# D1H register map
Vendor: Allwinner; File version: 1.0
Registers are 32-bit, read-write, reset 0x0 unless marked. A register's access mark holds for its fields unless they carry their own. Offsets are from the block's base; [hi:lo] are bit positions; lines under a group give offsets from that group; {n}, {i} and the like mark numbered series.

## USB1 (part 2 of 2) — USB2.0 HOST
Base 0x04200000
0x404 ohci_control_status_partition group — OHCI Control and Status Partition Register
  0x00 hc_control — OHCI Control Register
    [10] remote_wakeup_enable — This bit is used by HCD to enable or disable the remote wakeup feature upon the detection of upstream resume signaling. When this bit is set and the ResumeDetected bit in HcInterruptStatus is set, a remote wakeup is signaled to the host system. Setting this bit has no impact on the generation of hardware interrupt.
    [9] remote_wakeup_connected — This bit indicates whether HC supports remote wakeup signaling. If remote wakeup is supported and used by the system, it is the responsibility of system firmware to set this bit during POST. HC clear the bit upon a hardware reset but does not alter it upon a software reset. Remote wakeup signaling of the host system is host-bus-specific and is not described in this specification.
    [8] interrupt_routing — InterruptRouting This bit determines the routing of interrupts generated by events registered in HcInterruptStatus. If clear, all interrupt are routed to the normal host bus interrupt mechanism. If set interrupts are routed to the System Management Interrupt. HCD clears this bit upon a hardware reset, but it does not alter this bit upon a software reset. HCD uses this bit as a tag to indicate the ownership of HC.
    [7:6] host_controller_functional_state_for_usb — A transition to USBOperational from another state causes SOF generation to begin 1 ms later. HCD may determine whether HC has begun sending SOFs by reading the StartoFrame field of HcInterruptStatus. . This field may be changed by HC only when in the USBSUSPEND state. HC may move from the USBSUSPEND state to the USBRESUME state after detecting the resume signaling from a downstream port. . HC enters USBSUSPEND after a software reset, whereas it enters USBRESET after a hardware reset. The latter also resets the Root Hub and asserts subsequent reset signaling to downstream ports.
      0=USB_RESET; 1=USB_RESUME; 2=USB_OPERATIONAL; 3=USB_SUSPEND
    [5] bulk_list_enable — This bit is set to enable the processing of the Bulk list in the next Frame. If cleared by HCD, the processing of the Bulk list does not occur after the next SOF. HC checks this bit whenever it determines to process the list. When disabled, HCD may modify the list. If HcBulkCurrentED is pointing to an ED to be removed, HCD must advance the pointer by updating HcBulkCurrentED before re-enabling processing of the list.
    [3] control_list_enable — This bit is set to enable the processing of the Control list in the next Frame. If cleared by HCD, the processing of the Control list does not occur after the next SOF. HC must check this bit whenever it determines to process the list. When disabled, HCD may modify the list. If HcControlCurrentED is pointing to an ED to be removed, HCD must advance the pointer by updating HcControlCurrentED before re-enabling processing of the list.
    [3] isochronous_enable — This bit is used by HCD to enable/disable processing of isochronous EDs. While processing the periodic list in a Frame, HC checks the status of this bit when it finds an Isochronous ED (F=1). If set (enabled), HC continues processing the EDs. If cleared (disabled), HC halts processing of the periodic list (which now contains only isochronous EDs) and begins processing the Bulk/Control lists. Setting this bit is guaranteed to take effect in the next Frame (not the current Frame).
    [2] periodic_list_enable — This bit is set to enable the processing of periodic list in the next Frame. If cleared by HCD, processing of the periodic list does not occur after the next SOF. HC must check this bit before it starts processing the list.
    [1:0] control_bulk_service_ratio — This specifies the service ratio between Control and Bulk EDs. Before processing any of the nonperiodic lists, HC must compare the ratio specified with its internal count on how many nonempty Control EDs have been processed, in determining whether to continue serving another Control ED or switching to Bulk EDs. The internal count will be retained when crossing the frame boundary. In case of reset, HCD is responsible for restoring this value.
      {v}=R{v+1} ({v+1}:1) (v=0..3)
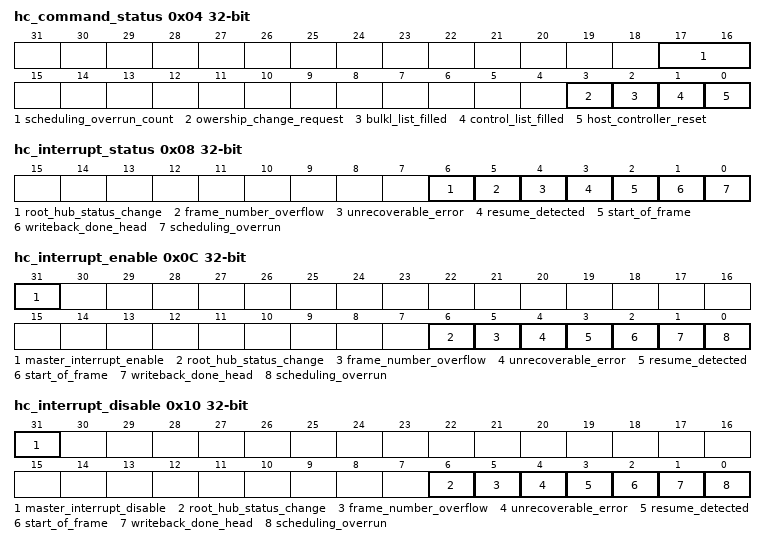
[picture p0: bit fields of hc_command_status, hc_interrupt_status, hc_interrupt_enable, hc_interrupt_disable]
  0x04 hc_command_status — OHCI Command Status Register
    [17:16] scheduling_overrun_count ro — SchedulingOverrunCoun . These bits are incremented on each scheduling overrun error. It is initialized to 00b and wraps around at 11b. This will be incremented when a scheduling overrun is detected even if SchedulingOverrun in has already been set. This is used by HCD to monitor any persistent scheduling problem.
    [3] owership_change_request — OwershipChangeRequest . This bit is set by an OS HCD to request a change of control of the HC. When set HC will set the OwnershipChange field in. After the changeover, this bit is cleared and remains so until the next request from OS HCD.
    [2] bulkl_list_filled — BulklListFilled . This bit is used to indicate whether there are any TDs on the Bulk list. It is set by HCD whenever it adds a TD to an ED in the Bulk list. When HC begins to process the head of the Bulk list, it checks BLF. As long as BulkListFilled is 0, HC will not start processing the Bulk list. If BulkListFilled is 1, HC will start processing the Bulk list and will set BF to 0. If HC finds a TD on the list, then HC will set BulkListFilled to 1 causing the Bulk list processing to continue. If no TD is found on the Bulk list, and if HCD does not set BulkListFilled , then BulkListFilled will still be 0 when HC completes processing the Bulk list and Bulk list processing will stop.
    [1] control_list_filled — ControlListFilled This bit is used to indicate whether there are any TDs on the Control list. It is set by HCD whenever it adds a TD to an ED in the Control list. . When HC begins to process the head of the Control list, it checks CLF. As long as ControlListFilled is 0, HC will not start processing the Control list. If CF is 1, HC will start processing the Control list and will set ControlListFilled to 0. If HC finds a TD on the list, then HC will set ControlListFilled to 1 causing the Control list processing to continue. If no TD is found on the Control list, and if the HCD does not set ControlListFilled , then ControlListFilled will still be 0 when HC completes processing the Control list and Control list processing will stop.
    [0] host_controller_reset — HostControllerReset . This bit is by HCD to initiate a software reset of HC. Regardless of the functional state of HC, it moves to the USBSuspend state in which most of the operational registers are reset except those stated otherwise; e.g, the InteruptRouting field of HcControl, and no Host bus accesses are allowed. This bit is cleared by HC upon the completion of the reset operation. The reset operation must be completed within 10 ms. This bit, when set, should not cause a reset to the Root Hub and no subsequent reset signaling should be asserted to its downstream ports.
  0x08 hc_interrupt_status — OHCI Interrupt Status Register
    [6] root_hub_status_change — RootHubStatusChange . This bit is set when the content of or the content of any of [ NumberofDownstreamPort ] has changed.
    [5] frame_number_overflow — FrameNumberOverflow . This bit is set when the MSb of (bit 15) changes value, from 0 to 1 or from 1 to 0, and after has been updated.
    [4] unrecoverable_error — UnrecoverableError . This bit is set when HC detects a system error not related to USB. HC should not proceed with any processing nor signaling before the system error has been corrected. HCD clears this bit after HC has been reset.
    [3] resume_detected — ResumeDetected . This bit is set when HC detects that a device on the USB is asserting resume signaling. It is the transition from no resume signaling to resume signaling causing this bit to be set. This bit is not set when HCD sets the USBRseume state.
    [2] start_of_frame — StartofFrame . This bit is set by HC at each start of frame and after the update of HccaFrameNumber. HC also generates a SOF token at the same time.
    [1] writeback_done_head — WritebackDoneHead . This bit is set immediately after HC has written to. Further updates of the will not occur until this bit has been cleared. HCD should only clear this bit after it has saved the content of HccaDoneHead.
    [0] scheduling_overrun — SchedulingOverrun . This bit is set when the USB schedule for the current Frame overruns and after the update of. A scheduling overrun will also cause the SchedulingOverrunCount of to be incremented.
  0x0C hc_interrupt_enable — OHCI Interrupt Enable Register
    [31] master_interrupt_enable — MasterInterruptEnable . A '0' writtern to this field is ignored by HC. A '1' written to this field enables interrupt generation due to events specified in the other bits of this register. This is used by HCD as Master Interrupt Enable.
    [6] root_hub_status_change — RootHubStatusChange Interrupt Enable
      0=IGNORE; 1=ENABLE (Enable interrupt generation due to Root Hub Status Change)
    [5] frame_number_overflow — FrameNumberOverflow Interrupt Enable
      0=IGNORE; 1=ENABLE (Enable interrupt generation due to Frame Number Overflow)
    [4] unrecoverable_error — UnrecoverableError Interrupt Enable
      0=IGNORE; 1=ENABLE (Enable interrupt generation due to Unrecoverable Error)
    [3] resume_detected — ResumeDetected Interrupt Enable
      0=IGNORE; 1=ENABLE (Enable interrupt generation due to Resume Detected)
    [2] start_of_frame — StartofFrame Interrupt Enable
      0=IGNORE; 1=ENABLE (Enable interrupt generation due to Start of Frame)
    [1] writeback_done_head — WritebackDoneHead Interrupt Enable
      0=IGNORE; 1=ENABLE (Enable interrupt generation due to Writeback Done Head)
    [0] scheduling_overrun — SchedulingOverrun Interrupt Enable
      0=IGNORE; 1=ENABLE (Enable interrupt generation due to Scheduling Overrun)
  0x10 hc_interrupt_disable — OHCI Interrupt Disable Register
    [31] master_interrupt_disable — MasterInterruptEnable . A '0' writtern to this field is ignored by HC. A '1' written to this field disables interrupt generation due to events specified in the other bits of this register. This field is set after a hardware or software reset.
    [6] root_hub_status_change — RootHubStatusChange Interrupt Disable
      0=IGNORE; 1=DISABLE (Disable interrupt generation due to Root Hub Status Change)
    [5] frame_number_overflow — FrameNumberOverflow Interrupt Disable
      0=IGNORE; 1=DISABLE (Disable interrupt generation due to Frame Number Overflow)
    [4] unrecoverable_error — UnrecoverableError Interrupt Disable
      0=IGNORE; 1=DISABLE (Disable interrupt generation due to Unrecoverable Error)
    [3] resume_detected — ResumeDetected Interrupt Disable
      0=IGNORE; 1=DISABLE (Disable interrupt generation due to Resume Detected)
    [2] start_of_frame — StartofFrame Interrupt Disable
      0=IGNORE; 1=DISABLE (Disable interrupt generation due to Start of Frame)
    [1] writeback_done_head — WritebackDoneHead Interrupt Disable
      0=IGNORE; 1=DISABLE (Disable interrupt generation due to Writeback Done Head)
    [0] scheduling_overrun — SchedulingOverrun Interrupt Disable
      0=IGNORE; 1=DISABLE (Disable interrupt generation due to Scheduling Overrun)
0x418 ohci_memory_pointer_partition group
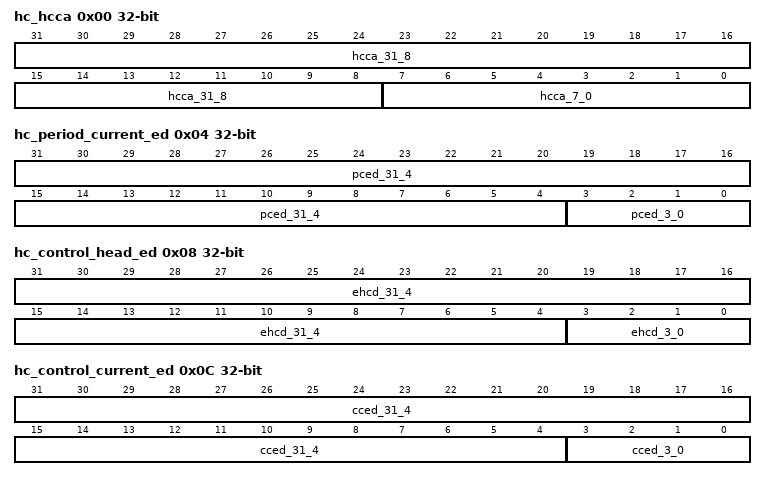
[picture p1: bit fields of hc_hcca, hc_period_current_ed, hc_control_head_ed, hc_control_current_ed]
  0x00 hc_hcca — OHCI HCCA Base
    [31:8] hcca_31_8 — This is the base address of the Host Controller Communication Area. This area is used to hold the control structures and the Interrupt table that are accessed by both the Host Controller and the Host Controller Driver.
    [7:0] hcca_7_0 ro — The alignment restriction in HcHCCA register is evaluated by examining the number of zeros in the lower order bits. The minimum alignment is 256 bytes, therefore, bits 0 through 7 must always return 0 when read.
  0x04 hc_period_current_ed — OHCI Period Current ED Base
    [31:4] pced_31_4 — This is used by HC to point to the head of one of the Periodec list which will be processed in the current Frame. The content of this register is updated by HC after a periodic ED has been processed. HCD may read the content in determining which ED is currently being processed at the time of reading.
    [3:0] pced_3_0 ro — Because the general TD length is 16 bytes, the memory structure for the TD must be aligned to a 16-byte boundary. So the lower bits in the PCED, through bit 0 to bit 3 must be zero in this field.
  0x08 hc_control_head_ed — OHCI Control Head ED Base
    [31:4] ehcd_31_4 — The HcControlHeadED register contains the physical address of the first Endpoint Descriptor of the Control list. HC traverse the Control list starting with the HcControlHeadED pointer. The content is loaded from HCCA during the initialization of HC.
    [3:0] ehcd_3_0 ro — Because the general TD length is 16 bytes, the memory structure for the TD must be aligned to a 16-byte boundary. So the lower bits in the PCED, through bit 0 to bit 3 must be zero in this field.
  0x0C hc_control_current_ed — OHCI Control Current ED Base
    [31:4] cced_31_4 — The pointer is advanced to the next ED after serving the present one. HC will continue processing the list from where it left off in the last Frame. When it reaches the end of the Control list, HC checks the ControlListFilled of in HcCommandStatus. If set, it copies the content of HcControlHeadED to HcControlCurrentED and clears the bit. If not set, it does nothing. . HCD is allowed to modify this register only when the ControlListEnable of HcControl is cleared. When set, HCD only reads the instantaneous value of this register. Initially, this is set to zero to indicate the end of the Control list.
    [3:0] cced_3_0 ro — Because the general TD length is 16 bytes, the memory structure for the TD must be aligned to a 16-byte boundary. So the lower bits in the PCED, through bit 0 to bit 3 must be zero in this field.
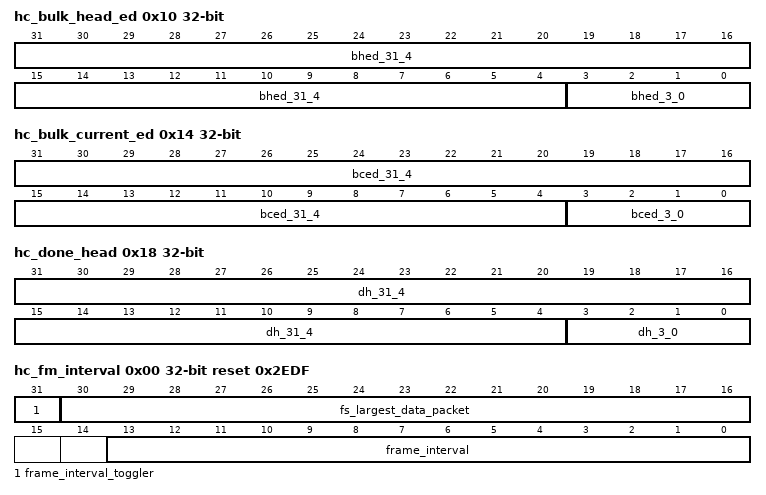
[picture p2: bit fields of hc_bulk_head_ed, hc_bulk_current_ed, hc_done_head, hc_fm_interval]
  0x10 hc_bulk_head_ed — OHCI Bulk Head ED Base
    [31:4] bhed_31_4 — The HcBulkHeadED register contains the physical address of the first Endpoint Descriptor of the Bulk list. HC traverses the Bulk list starting with the HcBulkHeadED pointer. The content is loaded from HCCA during the initialization of HC.
    [3:0] bhed_3_0 ro — Because the general TD length is 16 bytes, the memory structure for the TD must be aligned to a 16-byte boundary. So the lower bits in the PCED, through bit 0 to bit 3 must be zero in this field.
  0x14 hc_bulk_current_ed — OHCI Bulk Current ED Base
    [31:4] bced_31_4 — This is advanced to the next ED after the HC has served the present one. HC continues processing the list from where it left off in the last Frame. When it reaches the end of the Bulk list, HC checks the ControlListFilled of HcControl. If set, it copies the content of HcBulkHeadED to HcBulkCurrentED and clears the bit. If it is not set, it does nothing. HCD is only allowed to modify this register when the BulkListEnable of HcControl is cleared. When set, the HCD only reads the instantaneous value of this register. This is initially set to zero to indicate the end of the Bulk list.
    [3:0] bced_3_0 ro — Because the general TD length is 16 bytes, the memory structure for the TD must be aligned to a 16-byte boundary. So the lower bits in the PCED, through bit 0 to bit 3 must be zero in this field.
  0x18 hc_done_head — OHCI Done Head Base
    [31:4] dh_31_4 — When a TD is completed, HC writes the content of HcDoneHead to the NextTD field of the TD. HC then overwrites the content of HcDoneHead with the address of this TD. This is set to zero whenever HC writes the content of this register to HCCA. It also sets the WritebackDoneHead of HcInterruptStatus.
    [3:0] dh_3_0 ro — Because the general TD length is 16 bytes, the memory structure for the TD must be aligned to a 16-byte boundary. So the lower bits in the PCED, through bit 0 to bit 3 must be zero in this field.
0x434 ohci_frame_counter_partition group
  0x00 hc_fm_interval reset 0x2EDF — OHCI Frame Interval Register
    [31] frame_interval_toggler — FrameIntervalToggler HCD toggles this bit whenever it loads a new value to FrameInterval.
    [30:16] fs_largest_data_packet — FSLargestDataPacket . This field specifies a value which is loaded into the Largest Data Packet Counter at the beginning of each frame. The counter value represents the largest amount of data in bits which can be sent or received by the HC in a single transaction at any given time without causing scheduling overrun. The field value is calculated by the HCD.
    [13:0] frame_interval — FrameInterval . This specifies the interval between two consecutive SOFs in bit times. The nominal value is set to be 11,999. HCD should store the current value of this field before resetting HC. By setting the HostControllerReset field of as this will cause the HC to reset this field to its nominal value. HCD may choose to restore the stored value upon the completion of the Reset sequence.
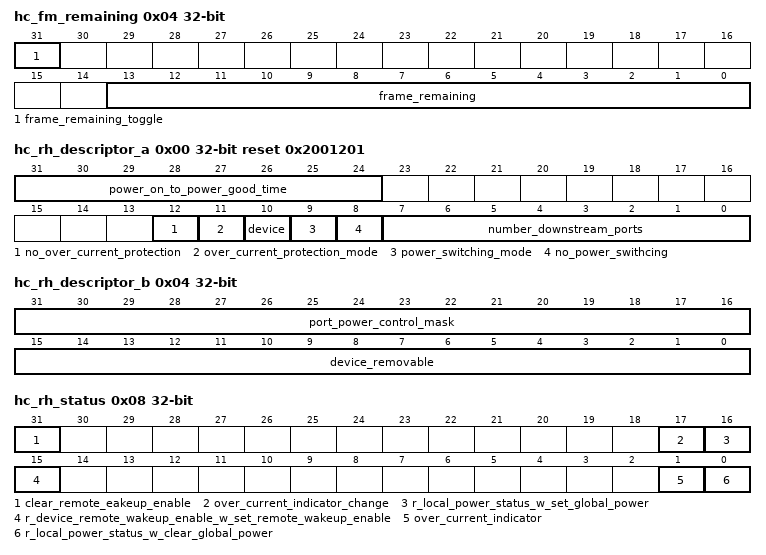
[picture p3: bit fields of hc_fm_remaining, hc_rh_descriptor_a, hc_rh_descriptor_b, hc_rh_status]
  0x04 hc_fm_remaining — OHCI Frame Remaining Register
    [31] frame_remaining_toggle — FrameRemaining Toggle . This bit is loaded from the FrameIntervalToggle field of whenever FrameRemaining reaches 0. This bit is used by HCD for the synchronization between FrameInterval and FrameRemaining.
    [13:0] frame_remaining — FrameRemaining . This counter is decremented at each bit time. When it reaches zero, it is reset by loading the FrameInterval value specified in at the next bit time boundary. When entering the USBOPERATIONAL state, HC re-loads the content with the FrameInterval of and uses the updated value from the next SOF.
  0x08 hc_fm_number — OHCI Frame Number Register
    [15:0] frame_number — FrameNumber . This is incremented when is re-loaded. It will be rolled over to 0x0 after 0x0ffff. When entering the USBOPERATIONAL state, this will be incremented automatically. The content will be written to HCCA after HC has incremented the FrameNumber at each frame boundary and sent a SOF but before HC reads the first ED in that Frame. After writing to HCCA, HC will set the StartofFrame in HcInterruptStatus
  0x0C hc_periodic_start — OHCI Periodic Start Register
    [13:0] periodic_start — PeriodicStart . After a hardware reset, this field is cleared. This is then set by HCD during the HC initialization. The value is calculated roughly as 10% off from. A typical value will be 0x2A3F (or 0x3e67). When reaches the value specified, processing of the periodic lists will have priority over Control/Bulk processing. HC will therefore start processing the Interrupt list after completing the current Control or Bulk transaction that is in progress.
  0x10 hc_ls_threshold reset 0x628 — OHCI LS Threshold Register
    [11:0] ls_threshold — LSThreshold . This field contains a value which is compared to the FrameRemaining field prior to initiating a Low Speed transaction. The transaction is started only if FrameRemaining this field. The value is calculated by HCD with the consideration of transmission and setup overhead.
0x448 ohci_root_hub_partition group
  0x00 hc_rh_descriptor_a reset 0x2001201 — OHCI Root Hub Descriptor Register A
    [31:24] power_on_to_power_good_time — PowerOnToPowerGoodTime[POTPGT] . This byte specifies the duration HCD has to wait before accessing a powered-on port of the Root Hub. It is implementation-specific. The unit of time is 2 ms. The duration is calculated as POTPGT * 2ms.
    [12] no_over_current_protection — NoOverCurrentProtection . This bit describes how the overcurrent status for the Root Hub ports are reported. When this bit is cleared, the OverCurrentProtectionMode field specifies global or per-port reporting.
      0=REPORT (Over-current status is reported collectively for all downstream ports); 1=NO_SUPPORT (No over-current protection supported)
    [11] over_current_protection_mode — OverCurrentProtectionMode . This bit describes how the overcurrent status for the Root Hub ports are reported. At reset, these fields should reflect the same mode as PowerSwitchingMode. This field is valid only if the NoOverCurrentProtection field is cleared. 0 Over-current status is reported collectively for all downstream ports. 1 Over-current status is reported on per-port basis.
      0=REPORT (Over-current status is reported collectively for all downstream ports); 1=REPORT_PERPORT (Over-current status is reported on per-port basis)
    [10] device ro — Device Type This bit specifies that the Root Hub is not a compound device. The Root Hub is not permitted to be a compound device. This field should always read/write 0.
    [9] power_switching_mode — PowerSwitchingMode . This bit is used to specify how the power switching of the Root Hub ports is controlled. It is implementation-specific. This field is only valid if the NoPowerSwitching field is cleared.
      0=SAME_TIME (All ports are powered at the same time); 1=INDIVIDUAL (Each port is powered individually. This mode allows port power to be controlled by either the global switch or per- port switching. If the PortPowerControlMask bit is set, the port responds only to port power commands ( Set/ClearPortPower ). If the port mask is cleared, then the port is controlled only by the global power switch ( Set/ClearGlobalPower ).)
    [8] no_power_swithcing — NoPowerSwithcing . These bits are used to specify whether power switching is supported or ports are always powered. It is implementation- specific. When this bit is cleared, the PowerSwitchingMode specifies global or per-port switching.
      0=SWITCHED (Ports are power switched); 1=ALWAYS (Ports are always powered on when the HC is powered on)
    [7:0] number_downstream_ports ro — NumberDownstreamPorts . These bits specify the number of downstream ports supported by the Root Hub. It is implementation-specific. The minimum number of ports is 1. The maximum number of ports supported.
  0x04 hc_rh_descriptor_b — OHCI Root Hub Descriptor Register B
    [31:16] port_power_control_mask — PortPowerControlMask . Each bit indicates if a port is affected by a global power control command when PowerSwitchingMode is set. When set, the port's power state is only affected by per-port power control ( Set/ClearPortPower ). When cleared, the port is controlled by the global power switch ( Set/ClearGlobalPower ). If the device is configured to global switching mode ( PowerSwitchingMode = 0 ), this field is not valid.
    [15:0] device_removable — DeviceRemovable . Each bit is dedicated to a port of the Root Hub. When cleared, the attached device is removable. When set, the attached device is not removable.
  0x08 hc_rh_status — OHCI Root Hub Status Register
    [31] clear_remote_eakeup_enable — (write)ClearRemoteWakeupEnable . Write a '1' clears DeviceRemoteWakeupEnable. Writing a '0' has no effect.
    [17] over_current_indicator_change — This bit is set by hardware when a change has occurred to the OverCurrentIndicator field of this register. The HCD clears this bit by writing a '1'. Writing a '0' has no effect.
    [16] r_local_power_status_w_set_global_power — (read)LocalPowerStatusChange . The Root Hub does not support the local power status features, thus, this bit is always read as '0'. (write)SetGlobalPower . In global power mode ( PowerSwitchingMode =0), This bit is written to '1' to turn on power to all ports (clear PortPowerStatus ). In per-port power mode, it sets PortPowerStatus only on ports whose PortPowerControlMask bit is not set. Writing a '0' has no effect.
    [15] r_device_remote_wakeup_enable_w_set_remote_wakeup_enable — (read)DeviceRemoteWakeupEnable . This bit enables a ConnectStatusChange bit as a resume event, causing a USBSUSPEND to USBRESUME state transition and setting the ResumeDetected interrupt. . 0 ConnectStatusChange is not a remote wakeup event. . 1 ConnectStatusChange is a remote wakeup event. (write)SetRemoteWakeupEnable . Writing a '1' sets DeviceRemoveWakeupEnable. Writing a '0' has no effect.
    [1] over_current_indicator — This bit reports overcurrent conditions when the global reporting is implemented. When set, an overcurrent condition exists. When cleared, all power operations are normal. If per-port overcurrent protection is implemented this bit is always '0'
    [0] r_local_power_status_w_clear_global_power — (Read)LocalPowerStatus . When read, this bit returns the LocalPowerStatus of the Root Hub. The Root Hub does not support the local power status feature; thus, this bit is always read as '0'. (Write)ClearGlobalPower . When write, this bit is operated as the ClearGlobalPower. In global power mode ( PowerSwitchingMode =0), This bit is written to '1' to turn off power to all ports (clear PortPowerStatus ). In per-port power mode, it clears PortPowerStatus only on ports whose PortPowerControlMask bit is not set. Writing a '0' has no effect.
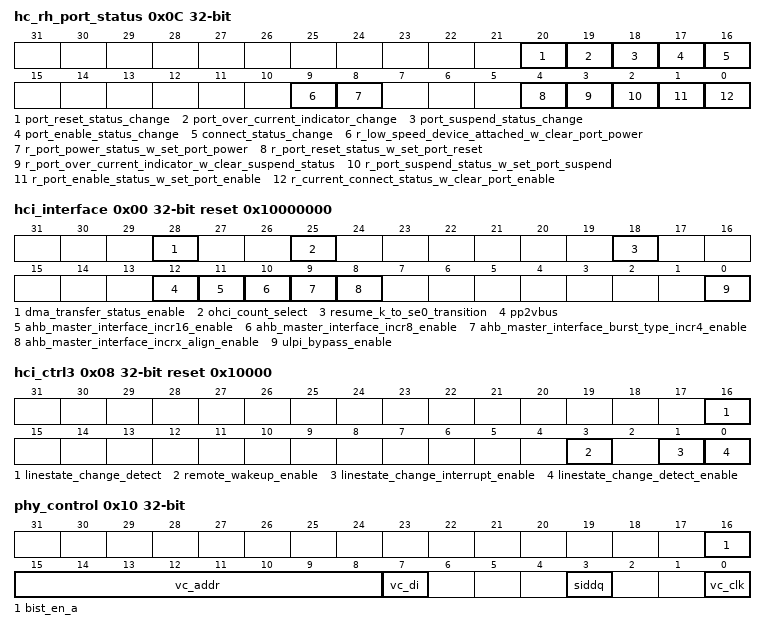
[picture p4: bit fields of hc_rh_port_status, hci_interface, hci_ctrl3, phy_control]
  0x0C hc_rh_port_status — OHCI Root Hub Port Status Register
    [20] port_reset_status_change — This bit is set at the end of the 10ms port reset signal. The HCD writes a '1' to clear this bit. Writing a '0' has no effect.
      0=NOC_COMPLETE (port reset is not complete); 1=COMPLETE (port reset is complete)
    [19] port_over_current_indicator_change — This bit is valid only if overcurrent conditions are reported on a per-port basis. This bit is set when Root Hub changes the PortOverCurrentIndicator bit. The HCD writes a ‘1’ to clear this bit. Writing a ‘0’ has no effect.
      0=NO_CHANGE (no change in PortOverCurrentIndicator); 1=CHANGE (PortOverCurrentIndicator has changed)
    [18] port_suspend_status_change — This bit is set when the full resume sequence has been completed. This sequence includes the 20-s resume pulse, LS EOP, and 3-ms resychronization delay. The HCD writes a '1' to clear this bit. Writing a '0' has no effect. This bit is also cleared when ResetStatusChange is set.
      0=NOT_COMPLETE (resume is not completed); 1=COMPLETE (resume is completed)
    [17] port_enable_status_change — This bit is set when hardware events cause the PortEnableStatus bit to be cleared. Changes from HCD writes do not set this bit. The HCD writes a '1' to clear this bit. Writing a '0' has no effect.
      0=NO_CHANGE (no change in PortEnableStatus); 1=CHANGE (PortEnableStatus has changed)
    [16] connect_status_change — This bit is set whenever a connect or disconnect event occurs. The HCD writes a '1' to clear this bit. Writing a '0' has no effect. If CurrentConnectStatus is cleared when a SetPortReset,SetPortEnable , or SetPortSuspend write occurs, this bit is set to force the driver to re-evaluate the connection status since these writes should not occur if the port is disconnected. . Note: If the DeviceRemovable[NDP] bit is set, this bit is set only after a Root Hub reset to inform the system that the device is attached.
      0=NO_CHANGE (no change in CurrentConnectStatus); 1=CHANGE (CurrentConnectStatus has changed)
    [9] r_low_speed_device_attached_w_clear_port_power — (read) LowSpeedDeviceAttached . This bit indicates the speed of the device attached to this port. When set, a Low Speed device is attached to this port. When clear, a Full Speed device is attached to this port. This field is valid only when the CurrentConnectStatus is set. . 0 full speed device attached . 1 low speed device attached (write) ClearPortPower . The HCD clears the PortPowerStatus bit by writing a '1' to this bit. Writing a '0' has no effect.
    [8] r_port_power_status_w_set_port_power — (read) PortPowerStatus . This bit reflects the port’s power status, regardless of the type of power switching implemented. This bit is cleared if an overcurrent condition is detected. HCD sets this bit by writing SetPortPower or SetGlobalPower. HCD clears this bit by writing ClearPortPower or ClearGlobalPower. Which power control switches are enabled is determined by PowerSwitchingMode and PortPortControlMask[NumberDownstreamPort]. In global switching mode(PowerSwitchingMode=0), Set/ClearGlobalPower controls this bit. In per-port power switching (PowerSwitchingMode=1), if the PortPowerControlMask[NDP] bit for the port is set, only Set/ClearPortPower commands are enabled. If the mask is not set, only Set/ClearGlobalPower commands are enabled. When port power is disabled, CurrentConnectStatus, PortEnableStatus, PortSuspendStatus, and PortResetStatus should be reset. . 0 port power is off . 1 port power is on (write) SetPortPower . The HCD writes a ‘1’ to set the PortPowerStatus bit. Writing a ‘0’ has no effect. . Note: This bit is always reads ‘1b’ if power switching is not supported.
    [4] r_port_reset_status_w_set_port_reset — (read) PortResetStatus . When this bit is set by a write to SetPortReset , port reset signaling is asserted. When reset is completed, this bit is cleared when PortResetStatusChange is set. This bit cannot be set if CurrentConnectStatus is cleared. . 0 port reset signal is not active . 1 port reset signal is active (write) SetPortReset . The HCD sets the port reset signaling by writing a '1' to this bit. Writing a '0' has no effect. If CurrentConnectStatus is cleared, this write does not set PortResetStatus , but instead sets ConnectStatusChange. This informs the driver that it attempted to reset a disconnected port.
    [3] r_port_over_current_indicator_w_clear_suspend_status — (read) PortOverCurrentIndicator . This bit is only valid when the Root Hub is configured in such a way that overcurrent conditions are reported on a per-port basis. If per-port overcurrent reporting is not supported, this bit is set to 0. If cleared, all power operations are normal for this port. If set, an overcurrent condition exists on this port. This bit always reflects the overcurrent input signal. 0 no overcurrent condition. 1 overcurrent condition detected. (write) ClearSuspendStatus . The HCD writes a '1' to initiate a resume. Writing a '0' has no effect. A resume is initiated only if PortSuspendStatus is set.
    [2] r_port_suspend_status_w_set_port_suspend — (read) PortSuspendStatus . This bit indicates the port is suspended or in the resume sequence. It is set by a SetSuspendState write and cleared when PortSuspendStatusChange is set at the end of the resume interval. This bit cannot be set if CurrentConnectStatus is cleared. This bit is also cleared when PortResetStatusChange is set at the end of the port reset or when the HC is placed in the USBRESUME state. If an upstream resume is in progress, it should propagate to the HC. . 0 port is not suspended . 1 port is suspended (write) SetPortSuspend . The HCD sets the PortSuspendStatus bit by writing a '1' to this bit. Writing a '0' has no effect. If CurrentConnectStatus is cleared, this write does not set PortSuspendStatus ; instead it sets ConnectStatusChange. This informs the driver that it attempted to suspend a disconnected port.
    [1] r_port_enable_status_w_set_port_enable — (read)PortEnableStatus . This bit indicates whether the port is enabled or disabled. The Root Hub may clear this bit when an overcurrent condition, disconnect event, switched-off power, or operational bus error such as babble is detected. This change also causes PortEnabledStatusChange to be set. HCD sets this bit by writing SetPortEnable and clears it by writing ClearPortEnable. This bit cannot be set when CurrentConnectStatus is cleared. This bit is also set, if not already, at the completion of a port reset when ResetStatusChange is set or port suspend when SuspendStatusChange is set. . 0 port is disabled . 1 port is enabled (write)SetPortEnable . The HCD sets PortEnableStatus by writing a ‘1’. Writing a ‘0’ has no effect. If CurrentConnectStatus is cleared, this write does not set PortEnableStatus, but instead sets ConnectStatusChange. This informs the driver that it attempted to enable a disconnected Port.
    [0] r_current_connect_status_w_clear_port_enable — (read) CurrentConnectStatus . This bit reflects the current state of the downstream port. . 0 No device connected . 1 Device connected (write) ClearPortEnable . The HCD writes a '1' to clear the PortEnableStatus bit. Writing '0' to this bit has no effect. The CurrentConnectStatus is not affected by any write. Note: This bit is always read '1' when the attached device is nonremovalble (DviceRemoveable[NumberDownstreamPort]).
0x800 hci_controller_phy_interface group — HCI Controller and PHY Interface Register
  0x00 hci_interface reset 0x10000000
    [28] dma_transfer_status_enable ro
      0=DISABLE; 1=ENABLE
    [25] ohci_count_select
      1=SIMULATION (Simulation mode. The counters will be much shorter then real time); 0=NORMAL (Normal mode. The counters will count full time)
    [18] resume_k_to_se0_transition
      1=WITHIN_2US (Within 2 us of the resume-K to SE0 transition); 0=RANDOM (Random time value of the resume-K to SE0 transition)
    [12] pp2vbus
      1=AUTO (ULPI wrapper interface will automatically set or clear DrvVbus register in ULPI PHY according to the port power status form the root hub); 0=IGNORE (ULPI wrapper will ignore the difference between power status of root hub and ULPI PHY)
    [11] ahb_master_interface_incr16_enable — Master interface INCR16 enable
      1=USE_INCR16 (Use INCR16 when appropriate); 0=NOT_USE_INCR16 (Do not use INCR16, use other enabled INCRX or unspecified length burst INCR)
    [10] ahb_master_interface_incr8_enable — Master interface INCR8 enable
      1=USE_INCR8 (Use INCR8 when appropriate); 0=NOT_USE_INCR8 (Do not use INCR8, use other enabled INCRX or unspecified length burst INCR)
    [9] ahb_master_interface_burst_type_incr4_enable — Master interface burst type INCR4 enable
      1=USE_INCR4 (Use INCR4 when appropriate); 0=NOT_USE_INCR4 (Do not use INCR4, use other enabled INCRX or unspecified length burst INCR)
    [8] ahb_master_interface_incrx_align_enable — Master interface INCRX align enable
      1=BURST_X_ALIGN_ADDRESS (Start INCRx burst only on burst x-align address); 0=ANY_DOUBLE_WORD_BOUNDARY (Start burst on any double word boundary Note: This bit must enable if any bit of bit[11:9] is enabled)
    [0] ulpi_bypass_enable
      1=UTMI (Enable UTMI interface, disable ULPI interface); 0=ULPI (Enable ULPI interface, disable UTMI interface)
  0x08 hci_ctrl3 reset 0x10000 — HCI Control Register
    [16] linestate_change_detect write-1-clears
      0=NOT_DECTED (Linestate change not dected); 1=DECTED (Linestate change dected Write '1' to clear.)
    [3] remote_wakeup_enable
      1=ENABLE; 0=DISABLE
    [1] linestate_change_interrupt_enable
      1=ENABLE; 0=DISABLE
    [0] linestate_change_detect_enable
      1=ENABLE; 0=DISABLE
  0x10 phy_control
    [16] bist_en_a
    [15:8] vc_addr
    [7] vc_di
    [3] siddq
      1=DISABLE (Write 1 to disable phy); 0=ENABLE (Write 0 to enable phy)
    [0] vc_clk
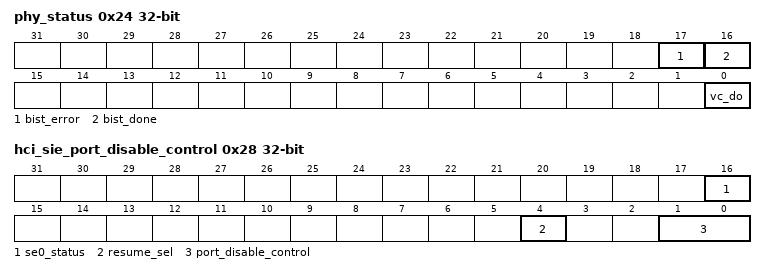
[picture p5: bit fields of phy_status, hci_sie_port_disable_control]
  0x24 phy_status ro
    [17] bist_error, [16] bist_done, [0] vc_do
  0x28 hci_sie_port_disable_control
    [16] se0_status — SE0 Status . This bit is set when no-se0 is detected before SOF when bit[1:0] is 10b or 11b
    [4] resume_sel — resume_sel . When set k-se0 transition 2 us, setting this bit to 1, which is cooperated with ss_utmi_backward_enb_i.
    [1:0] port_disable_control
      0=DISABLE (Port Disable when no-se0 detect before SOF); 2=NO_DISABLE (No Port Disable when no-se0 detect before SOF); 3=DISABLE_3_TIME_DETECT (Port Disable when no-se0 3 time detect before SOF during 8 frames)
